# STM32F334x8 register map
File version: 1.0
Registers are 32-bit, access not given, reset 0x0 unless marked. A register's access mark holds for its fields unless they carry their own. Offsets are from the block's base; [hi:lo] are bit positions; {n}, {i} and the like mark numbered series; 'fields as' and 'values as' point back to an identical list.

## HRTIM1_TIMA
Base 0x40017480
Same registers: HRTIM1_TIMB 0x40017500, HRTIM1_TIMC 0x40017580, HRTIM1_TIMD 0x40017600, HRTIM1_TIME 0x40017680
0x00 TIMxCR
0x04 TIMxISR
0x08 TIMxICR
0x0C TIMxDIER
0x10 CNTxR
0x14 PERxR
0x18 REPxR
0x1C CMP1xR
0x20 CMP1CxR
{0x1C+4i} CMP{i}xR (i=2..4)
0x30 CPT1xR
0x34 CPT2xR
0x38 DTxR
0x3C SETx1R
0x40 RSTx1R
0x44 SETx2R
0x48 RSTx2R
0x4C EEFxR1
0x50 EEFxR2
0x54 RSTxR
0x58 CHPxR
0x5C CPT1xCR
0x60 CPT2xCR
0x64 OUTxR
0x68 FLTxR

## DMA1
Base 0x40020000
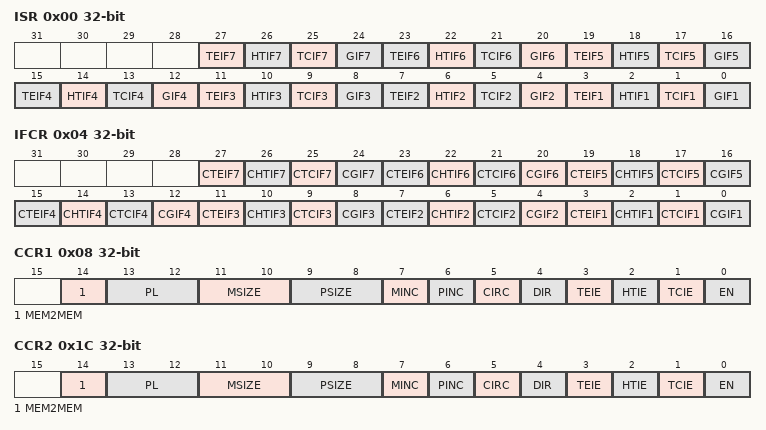
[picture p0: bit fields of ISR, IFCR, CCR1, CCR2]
0x00 ISR
  [4n-1] TEIF{n} (n=1..7), [4n-2] HTIF{n} (n=1..7), [4n-3] TCIF{n} (n=1..7), [4n-4] GIF{n} (n=1..7)
0x04 IFCR
  [4n-1] CTEIF{n} (n=1..7), [4n-2] CHTIF{n} (n=1..7), [4n-3] CTCIF{n} (n=1..7), [4n-4] CGIF{n} (n=1..7)
0x08 CCR1
  [14] MEM2MEM, [13:12] PL, [11:10] MSIZE, [9:8] PSIZE, [7] MINC, [6] PINC, [5] CIRC, [4] DIR, [3] TEIE, [2] HTIE, [1] TCIE, [0] EN
0x0C CNDTR1
  [15:0] NDT
{0x0+0x14*i} CPAR{i} (i=1..7)
  [31:0] PA
0x1C CCR2
  fields as CCR1
{0xC+0x14*i} CMAR{i} (i=1..7)
  [31:0] MA
0x20 CNDTR2
  [15:0] NDT
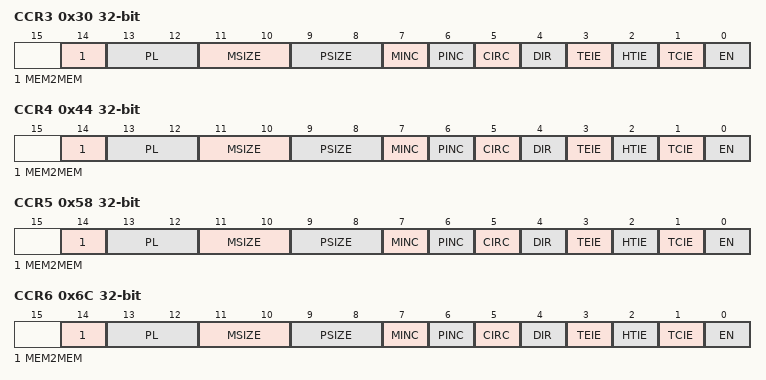
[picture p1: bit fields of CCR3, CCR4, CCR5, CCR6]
0x30 CCR3
  fields as CCR1
0x34 CNDTR3
  [15:0] NDT
0x44 CCR4
  fields as CCR1
0x48 CNDTR4
  [15:0] NDT
0x58 CCR5
  fields as CCR1
0x5C CNDTR5
  [15:0] NDT
0x6C CCR6
  fields as CCR1
0x70 CNDTR6
  [15:0] NDT
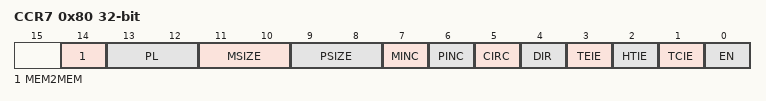
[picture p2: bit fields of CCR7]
0x80 CCR7
  fields as CCR1
0x84 CNDTR7
  [15:0] NDT

## RCC
Base 0x40021000
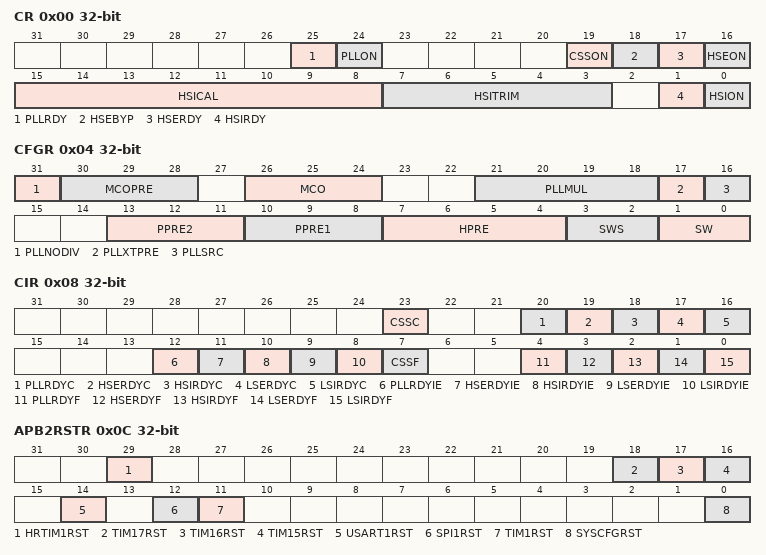
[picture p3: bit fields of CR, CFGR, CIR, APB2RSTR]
0x00 CR
  [25] PLLRDY, [24] PLLON, [19] CSSON, [18] HSEBYP, [17] HSERDY, [16] HSEON, [15:8] HSICAL, [7:3] HSITRIM, [1] HSIRDY, [0] HSION
0x04 CFGR
  [31] PLLNODIV, [30:28] MCOPRE, [26:24] MCO, [21:18] PLLMUL, [17] PLLXTPRE, [16] PLLSRC, [13:11] PPRE2, [10:8] PPRE1, [7:4] HPRE, [3:2] SWS, [1:0] SW
0x08 CIR
  [23] CSSC, [20] PLLRDYC, [19] HSERDYC, [18] HSIRDYC, [17] LSERDYC, [16] LSIRDYC, [12] PLLRDYIE, [11] HSERDYIE, [10] HSIRDYIE, [9] LSERDYIE, [8] LSIRDYIE, [7] CSSF, [4] PLLRDYF, [3] HSERDYF, [2] HSIRDYF, [1] LSERDYF, [0] LSIRDYF
0x0C APB2RSTR
  [29] HRTIM1RST, [18] TIM17RST, [17] TIM16RST, [16] TIM15RST, [14] USART1RST, [12] SPI1RST, [11] TIM1RST, [0] SYSCFGRST
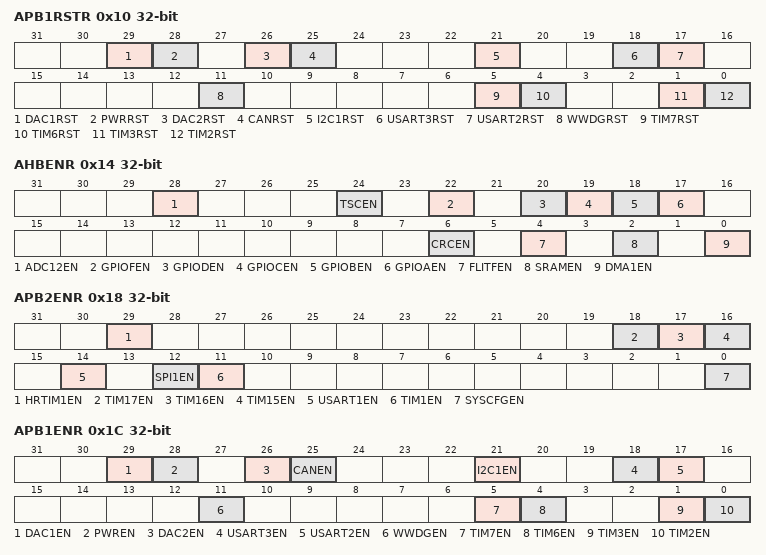
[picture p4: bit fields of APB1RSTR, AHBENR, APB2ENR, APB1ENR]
0x10 APB1RSTR
  [29] DAC1RST, [28] PWRRST, [26] DAC2RST, [25] CANRST, [21] I2C1RST, [18] USART3RST, [17] USART2RST, [11] WWDGRST, [5] TIM7RST, [4] TIM6RST, [1] TIM3RST, [0] TIM2RST
0x14 AHBENR
  [28] ADC12EN, [24] TSCEN, [22] GPIOFEN, [20] GPIODEN, [19] GPIOCEN, [18] GPIOBEN, [17] GPIOAEN, [6] CRCEN, [4] FLITFEN, [2] SRAMEN, [0] DMA1EN
0x18 APB2ENR
  [29] HRTIM1EN, [18] TIM17EN, [17] TIM16EN, [16] TIM15EN, [14] USART1EN, [12] SPI1EN, [11] TIM1EN, [0] SYSCFGEN
0x1C APB1ENR
  [29] DAC1EN, [28] PWREN, [26] DAC2EN, [25] CANEN, [21] I2C1EN, [18] USART3EN, [17] USART2EN, [11] WWDGEN, [5] TIM7EN, [4] TIM6EN, [1] TIM3EN, [0] TIM2EN
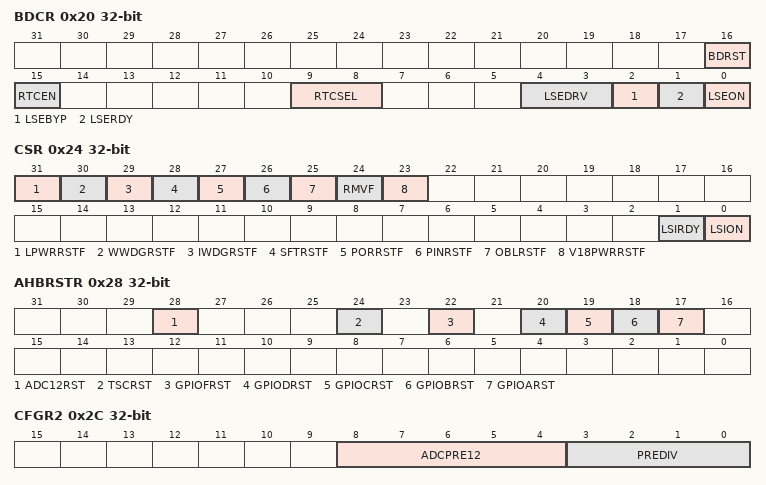
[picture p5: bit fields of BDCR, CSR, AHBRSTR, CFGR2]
0x20 BDCR
  [16] BDRST, [15] RTCEN, [9:8] RTCSEL, [4:3] LSEDRV, [2] LSEBYP, [1] LSERDY, [0] LSEON
0x24 CSR
  [31] LPWRRSTF, [30] WWDGRSTF, [29] IWDGRSTF, [28] SFTRSTF, [27] PORRSTF, [26] PINRSTF, [25] OBLRSTF, [24] RMVF, [23] V18PWRRSTF, [1] LSIRDY, [0] LSION
0x28 AHBRSTR
  [28] ADC12RST, [24] TSCRST, [22] GPIOFRST, [20] GPIODRST, [19] GPIOCRST, [18] GPIOBRST, [17] GPIOARST
0x2C CFGR2
  [8:4] ADCPRE12, [3:0] PREDIV
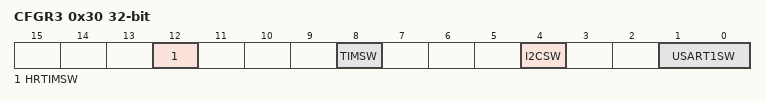
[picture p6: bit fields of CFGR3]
0x30 CFGR3
  [12] HRTIMSW, [8] TIMSW, [4] I2CSW, [1:0] USART1SW

## FLASH
Base 0x40022000
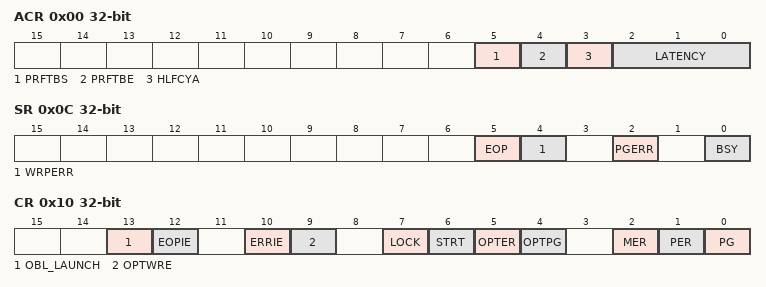
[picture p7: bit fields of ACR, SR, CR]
0x00 ACR
  [5] PRFTBS, [4] PRFTBE, [3] HLFCYA, [2:0] LATENCY
0x04 KEYR
  [31:0] FKEYR
0x08 OPTKEYR
0x0C SR
  [5] EOP, [4] WRPERR, [2] PGERR, [0] BSY
0x10 CR
  [13] OBL_LAUNCH, [12] EOPIE, [10] ERRIE, [9] OPTWRE, [7] LOCK, [6] STRT, [5] OPTER, [4] OPTPG, [2] MER, [1] PER, [0] PG
0x14 AR
  [31:0] FAR
0x1C OBR
  [31:24] DATA1, [23:16] DATA0, [14] SRAM_PE, [13] VDDA_MONITOR, [12] nBOOT1, [10] nRST_STDBY, [9] nRST_STOP, [14:8] USER, [2:1] RDPRT, [0] OPTERR
0x20 WRPR
  [31:0] WRP

## CRC
Base 0x40023000
0x00 DR
0x04 IDR 8-bit
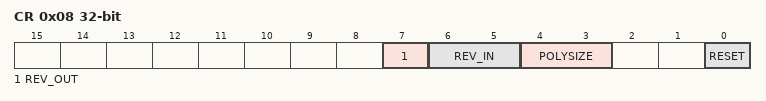
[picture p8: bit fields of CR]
0x08 CR
  [7] REV_OUT, [6:5] REV_IN, [4:3] POLYSIZE, [0] RESET
0x10 INIT
0x14 POL

## TSC
Base 0x40024000
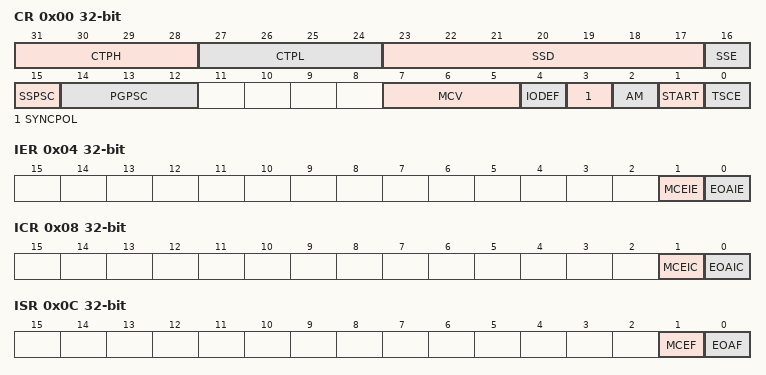
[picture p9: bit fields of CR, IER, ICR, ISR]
0x00 CR
  [31:28] CTPH, [27:24] CTPL, [23:17] SSD, [16] SSE, [15] SSPSC, [14:12] PGPSC, [7:5] MCV, [4] IODEF, [3] SYNCPOL, [2] AM, [1] START, [0] TSCE
0x04 IER
  [1] MCEIE, [0] EOAIE
0x08 ICR
  [1] MCEIC, [0] EOAIC
0x0C ISR
  [1] MCEF, [0] EOAF
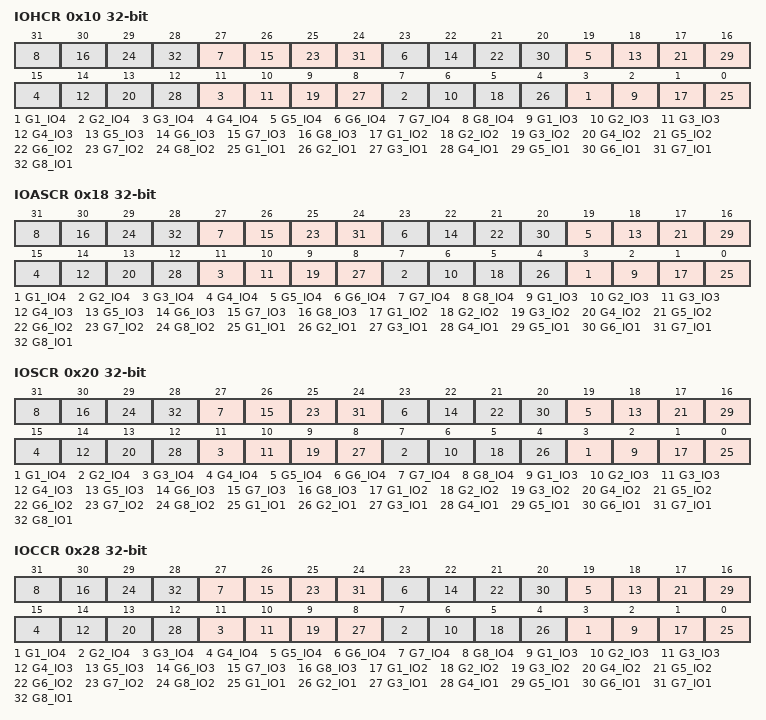
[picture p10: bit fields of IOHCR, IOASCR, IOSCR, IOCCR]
0x10 IOHCR
  [4n-1] G{n}_IO4 (n=1..8), [4n-2] G{n}_IO3 (n=1..8), [4n-3] G{n}_IO2 (n=1..8), [4n-4] G{n}_IO1 (n=1..8)
0x18 IOASCR
  fields as IOHCR
0x20 IOSCR
  fields as IOHCR
0x28 IOCCR
  fields as IOHCR
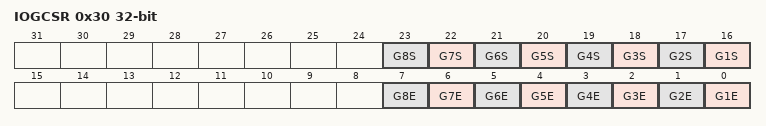
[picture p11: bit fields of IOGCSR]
0x30 IOGCSR
  [n+15] G{n}S (n=1..8), [n-1] G{n}E (n=1..8)
0x34 IOGXCR.0
  [13:0] CNT
0x38 IOGXCR.1
  [13:0] CNT
0x3C IOGXCR.2
  [13:0] CNT
0x40 IOGXCR.3
  [13:0] CNT
0x44 IOGXCR.4
  [13:0] CNT
0x48 IOGXCR.5
  [13:0] CNT
0x4C IOGXCR.6
  [13:0] CNT
0x50 IOGXCR.7
  [13:0] CNT

## GPIOA
Base 0x48000000
Same registers: GPIOB 0x48000400, GPIOC 0x48000800, GPIOD 0x48000C00, GPIOF 0x48001400
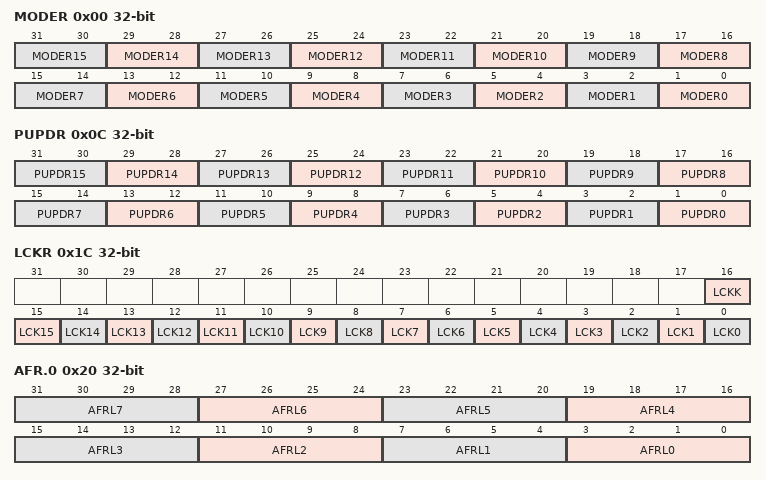
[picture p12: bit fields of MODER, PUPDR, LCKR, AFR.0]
0x00 MODER
  [2n+1:2n] MODER{n} (n=0..15)
0x04 OTYPER
0x08 OSPEEDR
0x0C PUPDR
  [2n+1:2n] PUPDR{n} (n=0..15)
0x10 IDR
0x14 ODR
0x18 BSRR
0x1C LCKR
  [16] LCKK, [n] LCK{n} (n=0..15)
0x20 AFR.0
  [4n+3:4n] AFRL{n} (n=0..7)
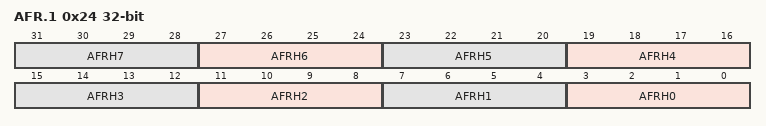
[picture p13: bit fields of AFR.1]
0x24 AFR.1
  [4n+3:4n] AFRH{n} (n=0..7)
0x28 BRR

## ADC1
Base 0x50000000
Same registers: ADC2 0x50000100
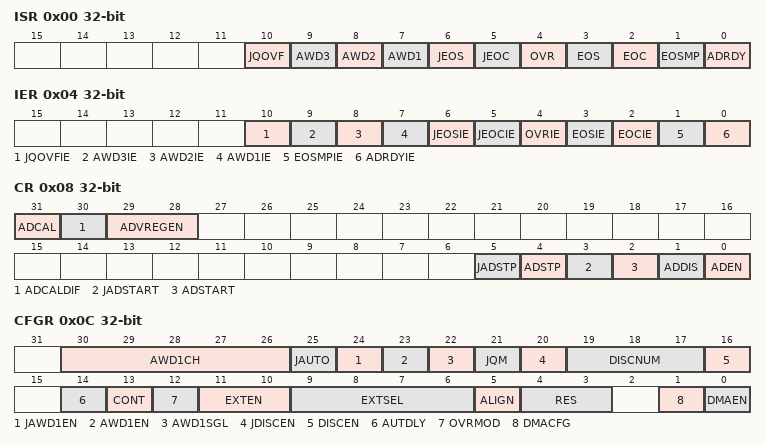
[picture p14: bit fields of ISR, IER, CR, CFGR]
0x00 ISR
  [10] JQOVF, [9] AWD3, [8] AWD2, [7] AWD1, [6] JEOS, [5] JEOC, [4] OVR, [3] EOS, [2] EOC, [1] EOSMP, [0] ADRDY
0x04 IER
  [10] JQOVFIE, [9] AWD3IE, [8] AWD2IE, [7] AWD1IE, [6] JEOSIE, [5] JEOCIE, [4] OVRIE, [3] EOSIE, [2] EOCIE, [1] EOSMPIE, [0] ADRDYIE
0x08 CR
  [31] ADCAL, [30] ADCALDIF, [29:28] ADVREGEN, [5] JADSTP, [4] ADSTP, [3] JADSTART, [2] ADSTART, [1] ADDIS, [0] ADEN
0x0C CFGR
  [30:26] AWD1CH, [25] JAUTO, [24] JAWD1EN, [23] AWD1EN, [22] AWD1SGL, [21] JQM, [20] JDISCEN, [19:17] DISCNUM, [16] DISCEN, [14] AUTDLY, [13] CONT, [12] OVRMOD, [11:10] EXTEN, [9:6] EXTSEL, [5] ALIGN, [4:3] RES, [1] DMACFG, [0] DMAEN
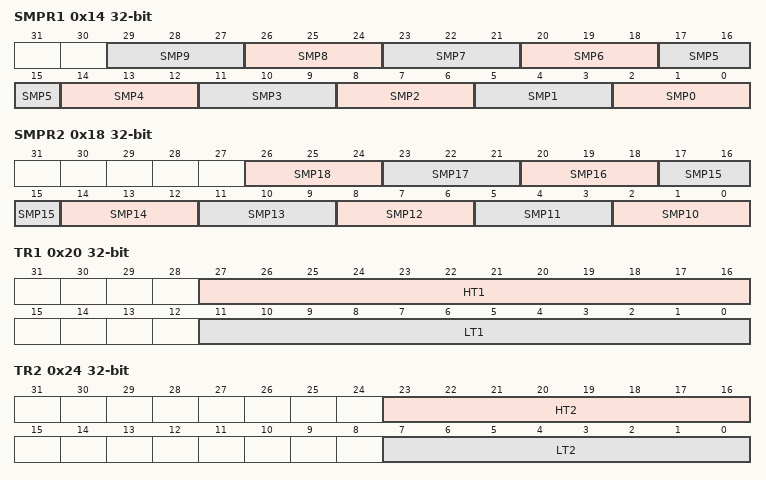
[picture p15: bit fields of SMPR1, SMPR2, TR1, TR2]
0x14 SMPR1
  [3n+2:3n] SMP{n} (n=0..9)
0x18 SMPR2
  [3n-28:3n-30] SMP{n} (n=10..18)
0x20 TR1
  [27:16] HT1, [11:0] LT1
0x24 TR2
  [23:16] HT2, [7:0] LT2
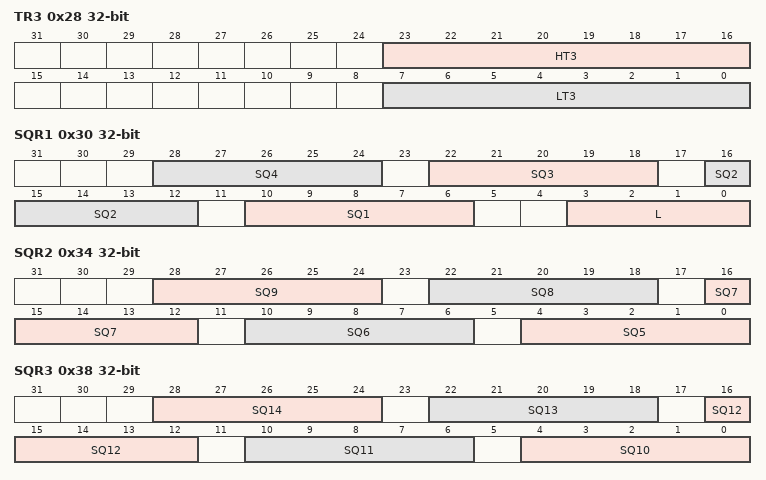
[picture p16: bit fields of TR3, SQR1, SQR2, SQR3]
0x28 TR3
  [23:16] HT3, [7:0] LT3
0x30 SQR1
  [6n+4:6n] SQ{n} (n=1..4), [3:0] L
0x34 SQR2
  [6n-26:6n-30] SQ{n} (n=5..9)
0x38 SQR3
  [6n-56:6n-60] SQ{n} (n=10..14)
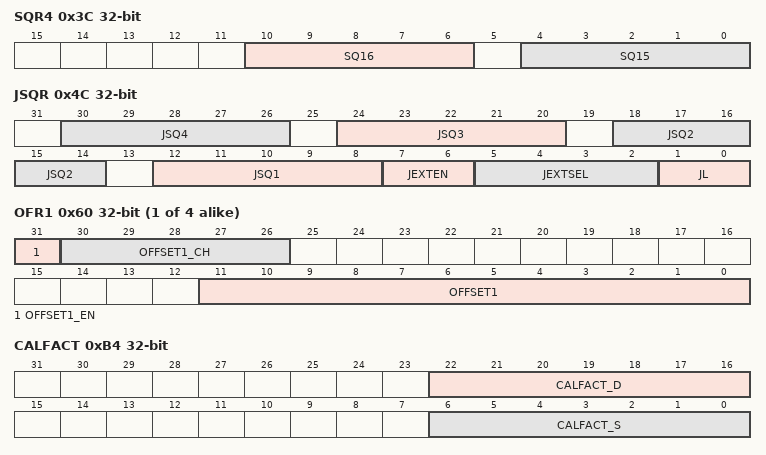
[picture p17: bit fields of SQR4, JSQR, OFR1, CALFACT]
0x3C SQR4
  [10:6] SQ16, [4:0] SQ15
0x40 DR
  [15:0] RDATA
0x4C JSQR
  [6n+6:6n+2] JSQ{n} (n=1..4), [7:6] JEXTEN, [5:2] JEXTSEL, [1:0] JL
{0x5C+4i} OFR{i} (i=1..4)
  [31] OFFSET{i}_EN, [30:26] OFFSET{i}_CH, [11:0] OFFSET{i}
{0x7C+4i} JDR{i} (i=1..4)
  [15:0] JDATA
0xA0 AWD2CR
  [18:1] AWD2CH
0xA4 AWD3CR
  [18:1] AWD3CH
0xB0 DIFSEL
  [18:1] DIFSEL
0xB4 CALFACT
  [22:16] CALFACT_D, [6:0] CALFACT_S

## ADC12_COMMON
Base 0x50000300
0x00 CSR
  [26] JQOVF_SLV, [25] AWD3_SLV, [24] AWD2_SLV, [23] AWD1_SLV, [22] JEOS_SLV, [21] JEOC_SLV, [20] OVR_SLV, [19] EOS_SLV, [18] EOC_SLV, [17] EOSMP_SLV, [16] ADRDY_SLV, [10] JQOVF_MST, [9] AWD3_MST, [8] AWD2_MST, [7] AWD1_MST, [6] JEOS_MST, [5] JEOC_MST, [4] OVR_MST, [3] EOS_MST, [2] EOC_MST, [1] EOSMP_MST, [0] ADRDY_MST
0x08 CCR
  [24] VBATEN, [23] TSEN, [22] VREFEN, [17:16] CKMODE, [15:14] MDMA, [13] DMACFG, [11:8] DELAY, [4:0] DUAL
0x0C CDR
  [31:16] RDATA_SLV, [15:0] RDATA_MST

## DBGMCU
Base 0xE0042000
0x00 IDCODE
  [31:16] REV_ID, [11:0] DEV_ID
0x04 CR
  [7:6] TRACE_MODE, [5] TRACE_IOEN, [2] DBG_STANDBY, [1] DBG_STOP, [0] DBG_SLEEP
0x08 APB1FZ
  [25] DBG_CAN_STOP, [21] DBG_I2C1_SMBUS_TIMEOUT, [12] DBG_IWDG_STOP, [11] DBG_WWDG_STOP, [10] DBG_RTC_STOP, [5] DBG_TIM7_STOP, [4] DBG_TIM6_STOP, [1] DBG_TIM3_STOP, [0] DBG_TIM2_STOP
0x0C APB2FZ
  [8] DBG_HRTIM1_STOP, [4] DBG_TIM17_STOP, [3] DBG_TIM16_STOP, [2] DBG_TIM15_STOP, [0] DBG_TIM1_STOP
